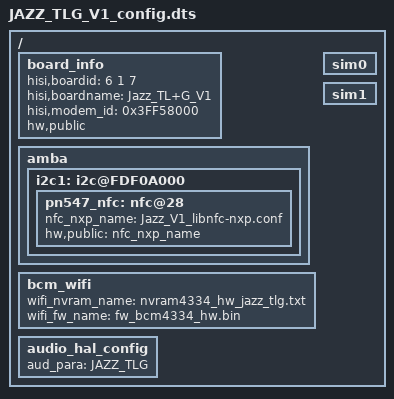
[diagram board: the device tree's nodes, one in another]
/*
 * Hisilicon Ltd.
 *
 * A15x4 A7x4
 *
 * It is only a demo for hisilicon hi3630 board. You show change the
 * address of each node according to datasheet.
 */

/dts-v1/;

/include/ "hisi_sim_hotplug.dtsi"

/include/ "JAZZ_ULG_V1_config.dtsi"
/include/ "hisi_3630_pin_JAZZ_TLG_V1.dtsi"
/include/ "hisi_3630_modem_JAZZ_TLG_V1.dtsi"
/ {
	board_info: board_info {
		hisi,boardid = <6 1 7>;
		hisi,boardname = "Jazz_TL+G_V1";
		hisi,modem_id = <0x3FF58000>;
		hw,public;
	};
	amba {
		i2c1: i2c@FDF0A000 {
			pn547_nfc:nfc@28 {
					  nfc_nxp_name = "Jazz_V1_libnfc-nxp.conf";
					  hw,public="nfc_nxp_name";
			};
		};
	};
	bcm_wifi {
		wifi_nvram_name = "nvram4334_hw_jazz_tlg.txt";
		wifi_fw_name = "fw_bcm4334_hw.bin";
		status = "ok";
	};
	sim0 {
		status = "ok";
	};
	sim1 {
		status = "ok";
	};
	audio_hal_config {
		aud_para = "JAZZ_TLG";
	};
};
